# TC37XPD register map
Vendor: Infineon; Series: ATVMC; File version: 100
CPU: other r0p0, little endian, MPU, FPU, vendor SysTick, 4 interrupt priority bits
Registers are 32-bit, read-write, reset 0x0 unless marked. A register's access mark holds for its fields unless they carry their own. Offsets are from the block's base; [hi:lo] are bit positions; lines under a group give offsets from that group; {n}, {i} and the like mark numbered series; 'fields as' and 'values as' point back to an identical list.

## GTM (part 4 of 13)
Base 0xF0100000
{0x8000+0x800*i} TOM[{i}] (i=0..2) group
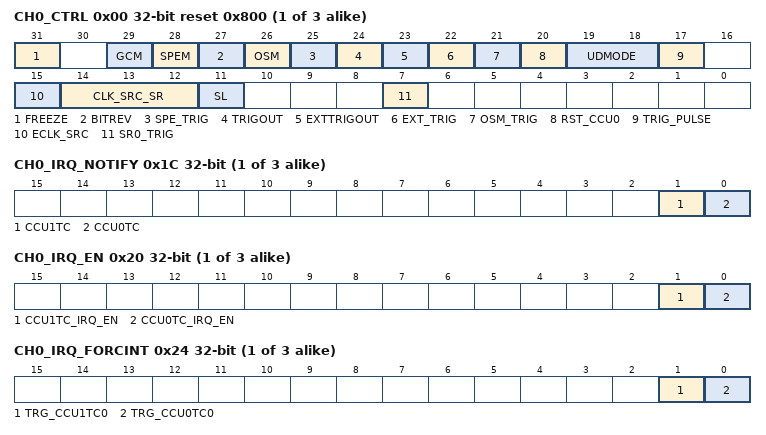
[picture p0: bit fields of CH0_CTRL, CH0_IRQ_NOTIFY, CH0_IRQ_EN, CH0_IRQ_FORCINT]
  0x00 CH0_CTRL reset 0x800 — TOM0 Channel 15 Control Register resetvalue={Application Reset:0x0800}
    [31] FREEZE
    [29] GCM — Gated Counter Mode enable. The Gated Counter mode is only available for TOM instances connected to an SPE module and only for channels 0 to 7.
    [28] SPEM — SPE output mode enable for channel. Note The SPE output mode is only implemented for TOM instances connected to an SPE module and only for TOM channels 0 to 7. Note For TOM channel 2 6 and 7 this bit defines in combination with bit SPE TRIG the source of output pin TOM i CH x OUT and if CN0 can be reset by TOM input signal SPE i NIPD .
    [27] BITREV — Bit reversing of output of counter register CN0. Note This bit enables the PCM mode of channel 15.
    [26] OSM — One shot mode. In this mode the counter CN0 counts for only one period. The length of period is defined by CM0. A write access to the register CN0 triggers the start of counting.
    [25] SPE_TRIG — SPE trigger to reset CN0. For TOM channel 2 6 and 7 this bit defines in combination with bit SPEM the source of output pin TOM i CH x OUT and if CN0 can be reset by TOM input signal SPE i NIPD. For TOM channel 8 and 9 this bit defines only if CN0 reset is defined by input signal SPE i NIPD or by configuration of RST CCU0. The output TOM i CH x OUT is not affected. The configuration bit SPEM is not available for these channels and thus assumed to be 0. If a configuration of SPEM SPE TRIG 0 1 or 1 0 is chosen i.e. CN0 is reset by signal SPE i NIPD the one shot mode in corresponding TOM channel should also be enabled by setting bit OSM 1 to generate one PWM pulse in case of trigger SPE i NIPD. In SPE module one of the trigger signals TOM i CH2 TRIG CCU1 TOM i CH6 TRIG CCU1 TOM i CH7 TRIG CCU1 TOM i CH8 TRIG CCU1 or TOM i CH9 TRIG CCU1 can be used to trigger the update of register SPE i OUT CTRL. If SPEM 0 SPEM 1
    [24] TRIGOUT — Trigger output selection output signal TRIG x of module TOM CH x
    [23] EXTTRIGOUT — TIM EXT CAPTURE x as potential output signal TRIG x
    [22] EXT_TRIG — Select TIM EXT CAPTURE x as trigger signal
    [21] OSM_TRIG — Enable trigger of one shot pulse by trigger signal OSM TRIG. Note This bit should only be set if bit OSM 1 and bit RST CCU0 0.
    [20] RST_CCU0 — Reset source of CCU0. On TOM channel 2 SPEM 1 has special meaning. If SPEM 1 the signal SPE NIPD triggers the reset of CN0 independent of RST CN0. This bit should only be set if bit OSM 0 i.e. in continuous mode .
    [19:18] UDMODE — Up down counter mode
    [17] TRIG_PULSE — Trigger output pulse length of one SYS CLK period
    [15] ECLK_SRC — Extend CLK SRC
    [14:12] CLK_SRC_SR — Clock source select for channel. The register CLK SRC is updated with the value of CLK SRC SR together with the update of register CM0 and CM1. The input of the FX clock divider depends on the value of FXCLK SEL see CMU . This register is a shadow register for the register CLK SRC. Thus if the CMU CLK source for PWM generation should be changed during operation the old CMU CLK has to operate until the update of the ATOM channels internal CLK SRC register by the CLK SRC SR content is done either by an end of a period or a forced update. If clock of channel is stopped i.e. ECLK SRC 0 and CLK SRC 101 110 111 the channel can only be restarted by resetting CLK SRC SR to a value of 000 to 100 and forcing an update via the force update mechanism. If ECLK SRC 0 ECLK SRC 1
    [11] SL — Signal level for duty cycle. If the output is disabled the output TOM OUT x is set to the inverse value of SL. Reset value depends on the hardware configuration chosen by silicon vendor.
    [7] SR0_TRIG — SR0 is used to generate a trigger on output TOM i CH x OUT T if equal to CN0. Note This bit should only be set if RST CCU0 of this channel is 0.
  0x04 CH0_SR0 — TOM0 Channel 15 CCU0 Compare Shadow Register resetvalue={Application Reset:0x0}
    [15:0] SR0 — TOM channel x shadow register SR0 for update of compare register CM0
  0x08 CH0_SR1 — TOM0 Channel 15 CCU1 Compare Shadow Register resetvalue={Application Reset:0x0}
    [15:0] SR1 — TOM channel x shadow register SR1 for update of compare register CM1
  0x0C CH0_CM0 — TOM0 Channel 15 CCU0 Compare Register resetvalue={Application Reset:0x0}
    [15:0] CM0 — TOM CCU0 compare register. Setting CM0 lt CM1 configures a duty cycle of 100 .
  0x10 CH0_CM1 — TOM0 Channel 15 CCU1 Compare Register resetvalue={Application Reset:0x0}
    [15:0] CM1 — TOM CCU1 compare register. Setting CM1 0 configures a duty cycle of 0 independent of the configured value of CM0.
  0x14 CH0_CN0 — TOM0 Channel 15 CCU0 Counter Register resetvalue={Application Reset:0x0}
    [15:0] CN0 — TOM CCU0 counter register. This counter is stopped if the TOM channel is disabled and not reset on an enable event of TOM channel.
  0x18 CH0_STAT ro — TOM0 Channel 15 Status Register resetvalue={Application Reset:0x0}
    [0] OL — Output level of output TOM OUT x . Reset value is the inverted value of SL bit which depends on the hardware configuration chosen by silicon vendor.
  0x1C CH0_IRQ_NOTIFY — TOM0 Channel 15 Interrupt Notification Register resetvalue={Application Reset:0x0}
    [1] CCU1TC — CCU1 Trigger condition interrupt for channel x. The notification of the interrupt is only triggered one time after reaching the condition CN0 gt CM1. To enable re trigger of the notification first the condition CN0 lt CM1 has to be reached. Note This bit will be cleared on a CPU write access of value 1. A read access leaves the bit unchanged. Note This description differs to the description in the Bosch spec.
    [0] CCU0TC — CCU0 Trigger condition interrupt for channel x. The notification of the interrupt is only triggered one time after reaching the condition CN0 gt CM0. To enable re trigger of the notification first the condition CN0 lt CM1 has to be reached. Note This bit will be cleared on a CPU write access of value 1. A read access leaves the bit unchanged. Note This description differs to the description in the Bosch spec.
  0x20 CH0_IRQ_EN — TOM0 Channel 15 Interrupt Enable Register resetvalue={Application Reset:0x0}
    [1] CCU1TC_IRQ_EN — TOM CCU1TC IRQ interrupt enable. Coding see bit 0.
    [0] CCU0TC_IRQ_EN — TOM CCU0TC IRQ interrupt enable
  0x24 CH0_IRQ_FORCINT — TOM0 Channel 15 Force Interrupt Register resetvalue={Application Reset:0x0}
    [1] TRG_CCU1TC0 — Trigger TOM CCU1TC0 IRQ interrupt by software. This bit is cleared automatically after write. This bit is write protected by bit RF PROT of register GTM CTRL.
    [0] TRG_CCU0TC0 — Trigger TOM CCU0TC0 IRQ interrupt by software. This bit is cleared automatically after write. This bit is write protected by bit RF PROT of register GTM CTRL
  0x28 CH0_IRQ_MODE — TOM0 Channel 15 Interrupt Mode Register resetvalue={Application Reset:0x0}
    [1:0] IRQ_MODE — IRQ mode selection. The interrupt modes are described in CROSSREFERENCE .
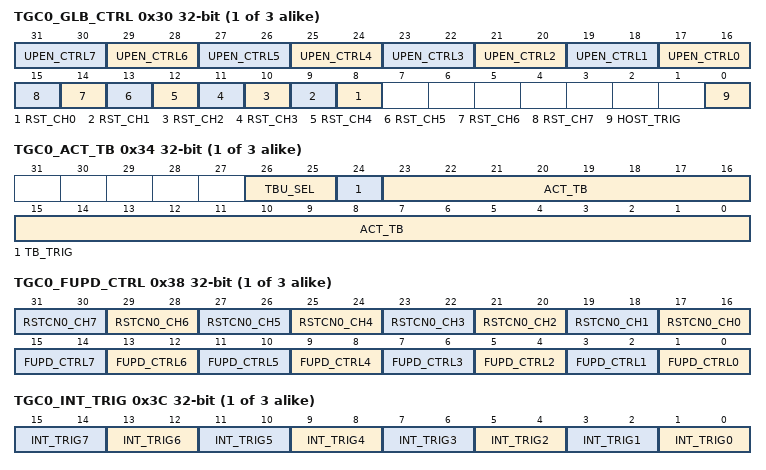
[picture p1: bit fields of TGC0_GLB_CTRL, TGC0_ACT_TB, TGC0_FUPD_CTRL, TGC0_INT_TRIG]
  0x30 TGC0_GLB_CTRL access per field — TOM0 TGC0 Global Control Register resetvalue={Application Reset:0x0}
    [2n+17:2n+16] UPEN_CTRL{n} rw (n=0..7) — TOM channel 7 enable update of register CM0 CM1 and CLK SRC from SR0 SR1 and CLK SRC SR. Write Read
    [n+8] RST_CH{n} wo (n=0..7) — Software reset of channel 7. This bit is cleared automatically after write by CPU. The channel register are set to their reset values and channel x operation is stopped immediately. The SR flip flop SOUR is set to 1 .
    [0] HOST_TRIG wo — Trigger request signal see TGC0 TGC1 to update the register ENDIS STAT and OUTEN STAT. This flag is reset automatically after triggering the update.
  0x34 TGC0_ACT_TB — TOM0 TGC0 Action Time Base Register resetvalue={Application Reset:0x0}
    [26:25] TBU_SEL — Selection of time base used for comparison. The bit combination 0b10 is only applicable if the TBU of the device contains three time base channels. Otherwise this bit combination is also reserved. Please refer to GTM Architecture block diagram on page 3 to determine the number of channels for TBU of this device.
    [24] TB_TRIG — Set trigger request. This flag is reset automatically if the selected time base unit TBU TS0 or TBU TS1 or TBU TS2 if present has reached the value ACT TB and the update of the register was triggered.
    [23:0] ACT_TB — Time base value. Specifies the signed compare value with selected signal TBU TS x x 0..2 If selected TBU TS x value is in the interval ACT TB 007FFFFFh ACT TB the event is in the past and the trigger is generated immediately. Otherwise the event is in the future and the trigger is generated if selected TBU TS x is equal to ACT TB .
  0x38 TGC0_FUPD_CTRL — TOM0 TGC0 Force Update Control Register resetvalue={Application Reset:0x0}
    [2n+17:2n+16] RSTCN0_CH{n} (n=0..7) — Reset CN0 of channel 7 on force update event. If enabled reset CN0 triggered by HOST TRIG ACT TB compare match or internal trigger. Write Read
    [2n+1:2n] FUPD_CTRL{n} (n=0..7) — Force update of TOM channel 7 operation registers. If enabled force update of register CM0 CM1 and CLK SRC triggered by HOST TRIG ACT TB compare match or internal trigger. Write Read The force update request is stored and executed synchronized to the selected FXCLK.
  0x3C TGC0_INT_TRIG — TOM0 TGC0 Internal Trigger Control Register resetvalue={Application Reset:0x0}
    [2n+1:2n] INT_TRIG{n} (n=0..7) — Select input signal TRIG 7 as a trigger source. Write Read
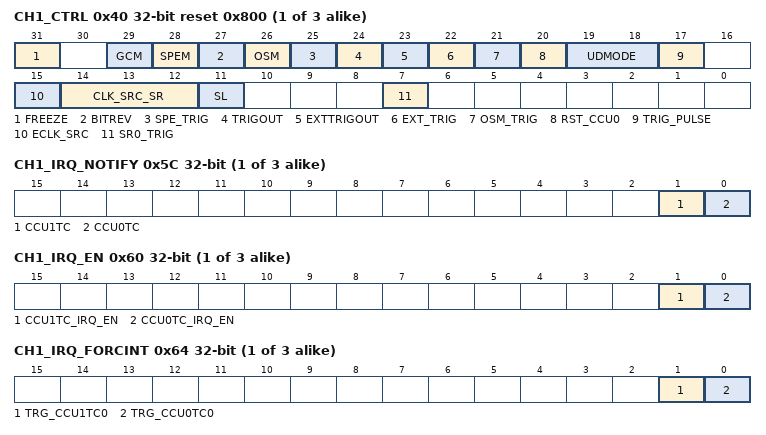
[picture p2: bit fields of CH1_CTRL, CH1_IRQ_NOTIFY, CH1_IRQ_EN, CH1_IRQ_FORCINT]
  0x40 CH1_CTRL reset 0x800 — TOM0 Channel 15 Control Register resetvalue={Application Reset:0x0800}
    fields as TOM[0].CH0_CTRL
  0x44 CH1_SR0 — TOM0 Channel 15 CCU0 Compare Shadow Register resetvalue={Application Reset:0x0}
    fields as TOM[0].CH0_SR0
  0x48 CH1_SR1 — TOM0 Channel 15 CCU1 Compare Shadow Register resetvalue={Application Reset:0x0}
    fields as TOM[0].CH0_SR1
  0x4C CH1_CM0 — TOM0 Channel 15 CCU0 Compare Register resetvalue={Application Reset:0x0}
    fields as TOM[0].CH0_CM0
  0x50 CH1_CM1 — TOM0 Channel 15 CCU1 Compare Register resetvalue={Application Reset:0x0}
    fields as TOM[0].CH0_CM1
  0x54 CH1_CN0 — TOM0 Channel 15 CCU0 Counter Register resetvalue={Application Reset:0x0}
    fields as TOM[0].CH0_CN0
  0x58 CH1_STAT ro — TOM0 Channel 15 Status Register resetvalue={Application Reset:0x0}
    fields as TOM[0].CH0_STAT
  0x5C CH1_IRQ_NOTIFY — TOM0 Channel 15 Interrupt Notification Register resetvalue={Application Reset:0x0}
    fields as TOM[0].CH0_IRQ_NOTIFY
  0x60 CH1_IRQ_EN — TOM0 Channel 15 Interrupt Enable Register resetvalue={Application Reset:0x0}
    fields as TOM[0].CH0_IRQ_EN
  0x64 CH1_IRQ_FORCINT — TOM0 Channel 15 Force Interrupt Register resetvalue={Application Reset:0x0}
    fields as TOM[0].CH0_IRQ_FORCINT
  0x68 CH1_IRQ_MODE — TOM0 Channel 15 Interrupt Mode Register resetvalue={Application Reset:0x0}
    fields as TOM[0].CH0_IRQ_MODE
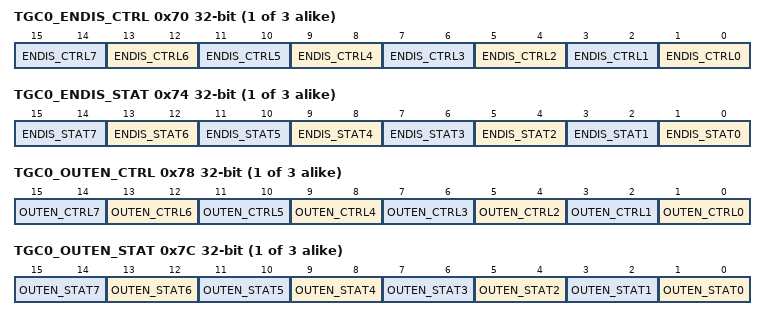
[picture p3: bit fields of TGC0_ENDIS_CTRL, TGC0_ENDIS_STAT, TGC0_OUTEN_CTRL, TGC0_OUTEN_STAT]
  0x70 TGC0_ENDIS_CTRL — TOM0 TGC0 Enable Disable Control Register resetvalue={Application Reset:0x0}
    [2n+1:2n] ENDIS_CTRL{n} (n=0..7) — TOM channel 7 enable disable update value. If FREEZE 0 If a TOM channel is disabled the counter CN0 is stopped and the output register of SOU unit is set to the inverse value of control bit SL. On an enable event the counter CN0 starts counting from its current value. If FREEZE 1 If a TOM channel is disabled the counter CN0 is stopped. On an enable event the counter CN0 starts counting from its current value. Write of following double bit values is possible If the output is disabled OUTEN 0 0 the TOM channel 0 output TOM i CH0 OUT is the inverted value of bit SL.
  0x74 TGC0_ENDIS_STAT — TOM0 TGC0 Enable Disable Status Register resetvalue={Application Reset:0x0}
    [2n+1:2n] ENDIS_STAT{n} (n=0..7) — TOM channel 7 enable disable update value. If FREEZE 0 If a TOM channel is disabled the counter CN0 is stopped and the output register of SOU unit is set to the inverse value of control bit SL. On an enable event the counter CN0 starts counting from its current value. If FREEZE 1 If a TOM channel is disabled the counter CN0 is stopped. On an enable event the counter CN0 starts counting from its current value. Write of following double bit values is possible
  0x78 TGC0_OUTEN_CTRL — TOM0 TGC0 Output Enable Control Register resetvalue={Application Reset:0x0}
    [2n+1:2n] OUTEN_CTRL{n} (n=0..7) — Output TOM i CH7 OUT enable disable update value. Write of following double bit values is possible If the channel is disabled ENDIS 0 0 or the output is disabled OUTEN 0 0 the TOM channel 0 output TOM i CH0 OUT is the inverted value of bit SL.
  0x7C TGC0_OUTEN_STAT — TOM0 TGC0 Output Enable Status Register resetvalue={Application Reset:0x0}
    [2n+1:2n] OUTEN_STAT{n} (n=0..7) — Control status of output TOM i CH7 OUT. Write of following double bit values is possible
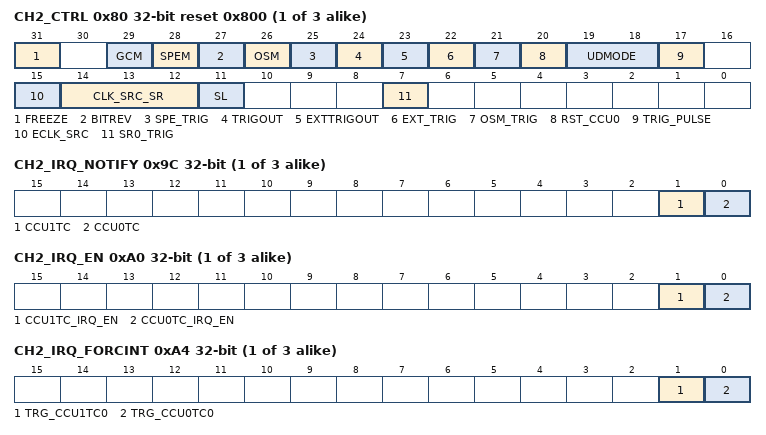
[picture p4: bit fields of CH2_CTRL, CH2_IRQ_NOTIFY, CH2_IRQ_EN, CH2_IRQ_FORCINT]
  0x80 CH2_CTRL reset 0x800 — TOM0 Channel 15 Control Register resetvalue={Application Reset:0x0800}
    fields as TOM[0].CH0_CTRL
  0x84 CH2_SR0 — TOM0 Channel 15 CCU0 Compare Shadow Register resetvalue={Application Reset:0x0}
    fields as TOM[0].CH0_SR0
  0x88 CH2_SR1 — TOM0 Channel 15 CCU1 Compare Shadow Register resetvalue={Application Reset:0x0}
    fields as TOM[0].CH0_SR1
  0x8C CH2_CM0 — TOM0 Channel 15 CCU0 Compare Register resetvalue={Application Reset:0x0}
    fields as TOM[0].CH0_CM0
  0x90 CH2_CM1 — TOM0 Channel 15 CCU1 Compare Register resetvalue={Application Reset:0x0}
    fields as TOM[0].CH0_CM1
  0x94 CH2_CN0 — TOM0 Channel 15 CCU0 Counter Register resetvalue={Application Reset:0x0}
    fields as TOM[0].CH0_CN0
  0x98 CH2_STAT ro — TOM0 Channel 15 Status Register resetvalue={Application Reset:0x0}
    fields as TOM[0].CH0_STAT
  0x9C CH2_IRQ_NOTIFY — TOM0 Channel 15 Interrupt Notification Register resetvalue={Application Reset:0x0}
    fields as TOM[0].CH0_IRQ_NOTIFY
  0xA0 CH2_IRQ_EN — TOM0 Channel 15 Interrupt Enable Register resetvalue={Application Reset:0x0}
    fields as TOM[0].CH0_IRQ_EN
  0xA4 CH2_IRQ_FORCINT — TOM0 Channel 15 Force Interrupt Register resetvalue={Application Reset:0x0}
    fields as TOM[0].CH0_IRQ_FORCINT
  0xA8 CH2_IRQ_MODE — TOM0 Channel 15 Interrupt Mode Register resetvalue={Application Reset:0x0}
    fields as TOM[0].CH0_IRQ_MODE
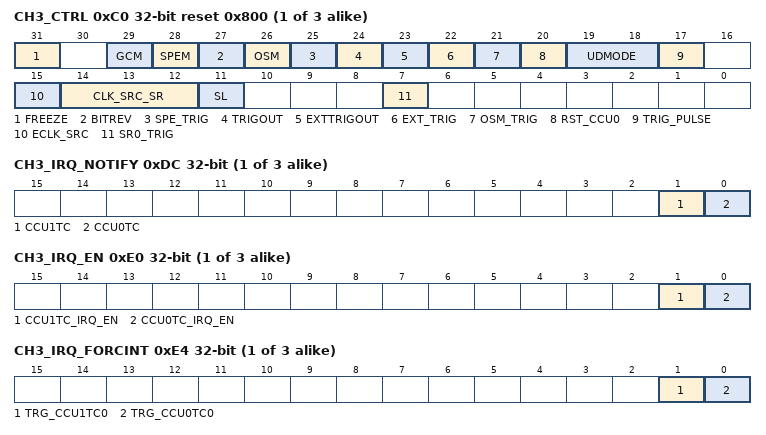
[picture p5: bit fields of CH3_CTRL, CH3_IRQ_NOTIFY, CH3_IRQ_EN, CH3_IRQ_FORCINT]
  0xC0 CH3_CTRL reset 0x800 — TOM0 Channel 15 Control Register resetvalue={Application Reset:0x0800}
    fields as TOM[0].CH0_CTRL
  0xC4 CH3_SR0 — TOM0 Channel 15 CCU0 Compare Shadow Register resetvalue={Application Reset:0x0}
    fields as TOM[0].CH0_SR0
  0xC8 CH3_SR1 — TOM0 Channel 15 CCU1 Compare Shadow Register resetvalue={Application Reset:0x0}
    fields as TOM[0].CH0_SR1
  0xCC CH3_CM0 — TOM0 Channel 15 CCU0 Compare Register resetvalue={Application Reset:0x0}
    fields as TOM[0].CH0_CM0
  0xD0 CH3_CM1 — TOM0 Channel 15 CCU1 Compare Register resetvalue={Application Reset:0x0}
    fields as TOM[0].CH0_CM1
  0xD4 CH3_CN0 — TOM0 Channel 15 CCU0 Counter Register resetvalue={Application Reset:0x0}
    fields as TOM[0].CH0_CN0
  0xD8 CH3_STAT ro — TOM0 Channel 15 Status Register resetvalue={Application Reset:0x0}
    fields as TOM[0].CH0_STAT
  0xDC CH3_IRQ_NOTIFY — TOM0 Channel 15 Interrupt Notification Register resetvalue={Application Reset:0x0}
    fields as TOM[0].CH0_IRQ_NOTIFY
  0xE0 CH3_IRQ_EN — TOM0 Channel 15 Interrupt Enable Register resetvalue={Application Reset:0x0}
    fields as TOM[0].CH0_IRQ_EN
  0xE4 CH3_IRQ_FORCINT — TOM0 Channel 15 Force Interrupt Register resetvalue={Application Reset:0x0}
    fields as TOM[0].CH0_IRQ_FORCINT
  0xE8 CH3_IRQ_MODE — TOM0 Channel 15 Interrupt Mode Register resetvalue={Application Reset:0x0}
    fields as TOM[0].CH0_IRQ_MODE
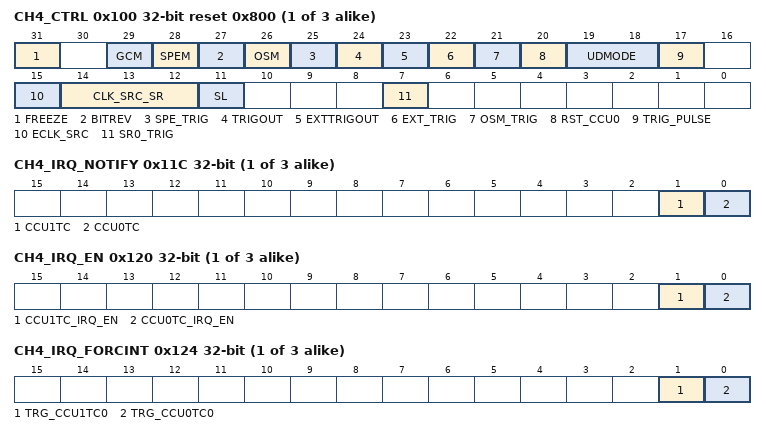
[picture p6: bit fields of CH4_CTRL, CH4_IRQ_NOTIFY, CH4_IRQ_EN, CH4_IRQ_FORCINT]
  0x100 CH4_CTRL reset 0x800 — TOM0 Channel 15 Control Register resetvalue={Application Reset:0x0800}
    fields as TOM[0].CH0_CTRL
  0x104 CH4_SR0 — TOM0 Channel 15 CCU0 Compare Shadow Register resetvalue={Application Reset:0x0}
    fields as TOM[0].CH0_SR0
  0x108 CH4_SR1 — TOM0 Channel 15 CCU1 Compare Shadow Register resetvalue={Application Reset:0x0}
    fields as TOM[0].CH0_SR1
  0x10C CH4_CM0 — TOM0 Channel 15 CCU0 Compare Register resetvalue={Application Reset:0x0}
    fields as TOM[0].CH0_CM0
  0x110 CH4_CM1 — TOM0 Channel 15 CCU1 Compare Register resetvalue={Application Reset:0x0}
    fields as TOM[0].CH0_CM1
  0x114 CH4_CN0 — TOM0 Channel 15 CCU0 Counter Register resetvalue={Application Reset:0x0}
    fields as TOM[0].CH0_CN0
  0x118 CH4_STAT ro — TOM0 Channel 15 Status Register resetvalue={Application Reset:0x0}
    fields as TOM[0].CH0_STAT
  0x11C CH4_IRQ_NOTIFY — TOM0 Channel 15 Interrupt Notification Register resetvalue={Application Reset:0x0}
    fields as TOM[0].CH0_IRQ_NOTIFY
  0x120 CH4_IRQ_EN — TOM0 Channel 15 Interrupt Enable Register resetvalue={Application Reset:0x0}
    fields as TOM[0].CH0_IRQ_EN
  0x124 CH4_IRQ_FORCINT — TOM0 Channel 15 Force Interrupt Register resetvalue={Application Reset:0x0}
    fields as TOM[0].CH0_IRQ_FORCINT
  0x128 CH4_IRQ_MODE — TOM0 Channel 15 Interrupt Mode Register resetvalue={Application Reset:0x0}
    fields as TOM[0].CH0_IRQ_MODE
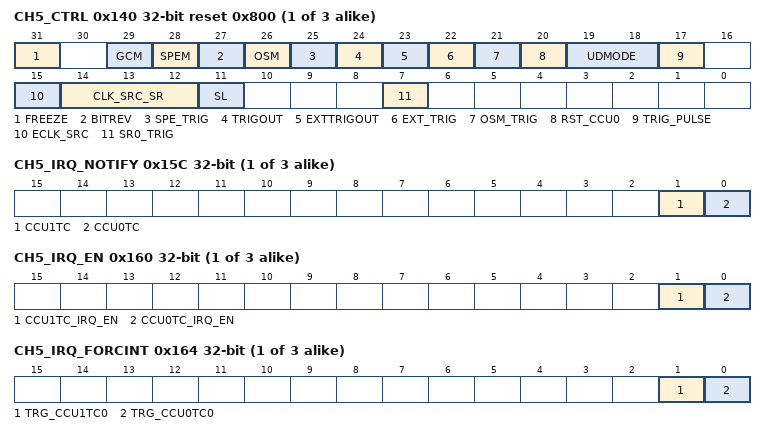
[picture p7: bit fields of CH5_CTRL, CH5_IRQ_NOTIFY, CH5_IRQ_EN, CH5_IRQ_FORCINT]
  0x140 CH5_CTRL reset 0x800 — TOM0 Channel 15 Control Register resetvalue={Application Reset:0x0800}
    fields as TOM[0].CH0_CTRL
  0x144 CH5_SR0 — TOM0 Channel 15 CCU0 Compare Shadow Register resetvalue={Application Reset:0x0}
    fields as TOM[0].CH0_SR0
  0x148 CH5_SR1 — TOM0 Channel 15 CCU1 Compare Shadow Register resetvalue={Application Reset:0x0}
    fields as TOM[0].CH0_SR1
  0x14C CH5_CM0 — TOM0 Channel 15 CCU0 Compare Register resetvalue={Application Reset:0x0}
    fields as TOM[0].CH0_CM0
  0x150 CH5_CM1 — TOM0 Channel 15 CCU1 Compare Register resetvalue={Application Reset:0x0}
    fields as TOM[0].CH0_CM1
  0x154 CH5_CN0 — TOM0 Channel 15 CCU0 Counter Register resetvalue={Application Reset:0x0}
    fields as TOM[0].CH0_CN0
  0x158 CH5_STAT ro — TOM0 Channel 15 Status Register resetvalue={Application Reset:0x0}
    fields as TOM[0].CH0_STAT
  0x15C CH5_IRQ_NOTIFY — TOM0 Channel 15 Interrupt Notification Register resetvalue={Application Reset:0x0}
    fields as TOM[0].CH0_IRQ_NOTIFY
  0x160 CH5_IRQ_EN — TOM0 Channel 15 Interrupt Enable Register resetvalue={Application Reset:0x0}
    fields as TOM[0].CH0_IRQ_EN
  0x164 CH5_IRQ_FORCINT — TOM0 Channel 15 Force Interrupt Register resetvalue={Application Reset:0x0}
    fields as TOM[0].CH0_IRQ_FORCINT
  0x168 CH5_IRQ_MODE — TOM0 Channel 15 Interrupt Mode Register resetvalue={Application Reset:0x0}
    fields as TOM[0].CH0_IRQ_MODE
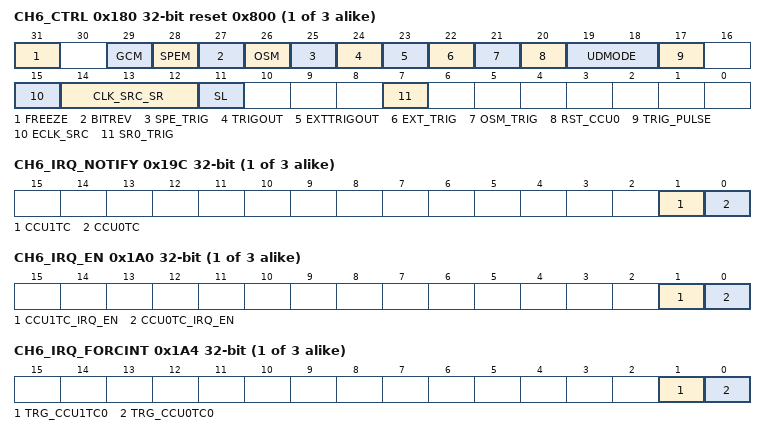
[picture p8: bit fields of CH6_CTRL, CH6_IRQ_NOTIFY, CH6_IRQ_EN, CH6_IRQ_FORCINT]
  0x180 CH6_CTRL reset 0x800 — TOM0 Channel 15 Control Register resetvalue={Application Reset:0x0800}
    fields as TOM[0].CH0_CTRL
  0x184 CH6_SR0 — TOM0 Channel 15 CCU0 Compare Shadow Register resetvalue={Application Reset:0x0}
    fields as TOM[0].CH0_SR0
  0x188 CH6_SR1 — TOM0 Channel 15 CCU1 Compare Shadow Register resetvalue={Application Reset:0x0}
    fields as TOM[0].CH0_SR1
  0x18C CH6_CM0 — TOM0 Channel 15 CCU0 Compare Register resetvalue={Application Reset:0x0}
    fields as TOM[0].CH0_CM0
  0x190 CH6_CM1 — TOM0 Channel 15 CCU1 Compare Register resetvalue={Application Reset:0x0}
    fields as TOM[0].CH0_CM1
  0x194 CH6_CN0 — TOM0 Channel 15 CCU0 Counter Register resetvalue={Application Reset:0x0}
    fields as TOM[0].CH0_CN0
  0x198 CH6_STAT ro — TOM0 Channel 15 Status Register resetvalue={Application Reset:0x0}
    fields as TOM[0].CH0_STAT
  0x19C CH6_IRQ_NOTIFY — TOM0 Channel 15 Interrupt Notification Register resetvalue={Application Reset:0x0}
    fields as TOM[0].CH0_IRQ_NOTIFY
  0x1A0 CH6_IRQ_EN — TOM0 Channel 15 Interrupt Enable Register resetvalue={Application Reset:0x0}
    fields as TOM[0].CH0_IRQ_EN
  0x1A4 CH6_IRQ_FORCINT — TOM0 Channel 15 Force Interrupt Register resetvalue={Application Reset:0x0}
    fields as TOM[0].CH0_IRQ_FORCINT
  0x1A8 CH6_IRQ_MODE — TOM0 Channel 15 Interrupt Mode Register resetvalue={Application Reset:0x0}
    fields as TOM[0].CH0_IRQ_MODE
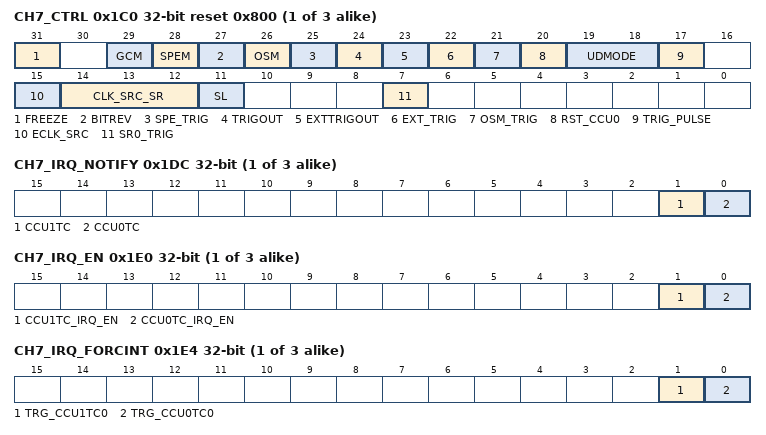
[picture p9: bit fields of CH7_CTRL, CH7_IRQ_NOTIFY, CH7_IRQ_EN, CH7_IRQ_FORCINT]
  0x1C0 CH7_CTRL reset 0x800 — TOM0 Channel 15 Control Register resetvalue={Application Reset:0x0800}
    fields as TOM[0].CH0_CTRL
  0x1C4 CH7_SR0 — TOM0 Channel 15 CCU0 Compare Shadow Register resetvalue={Application Reset:0x0}
    fields as TOM[0].CH0_SR0
  0x1C8 CH7_SR1 — TOM0 Channel 15 CCU1 Compare Shadow Register resetvalue={Application Reset:0x0}
    fields as TOM[0].CH0_SR1
  0x1CC CH7_CM0 — TOM0 Channel 15 CCU0 Compare Register resetvalue={Application Reset:0x0}
    fields as TOM[0].CH0_CM0
  0x1D0 CH7_CM1 — TOM0 Channel 15 CCU1 Compare Register resetvalue={Application Reset:0x0}
    fields as TOM[0].CH0_CM1
  0x1D4 CH7_CN0 — TOM0 Channel 15 CCU0 Counter Register resetvalue={Application Reset:0x0}
    fields as TOM[0].CH0_CN0
  0x1D8 CH7_STAT ro — TOM0 Channel 15 Status Register resetvalue={Application Reset:0x0}
    fields as TOM[0].CH0_STAT
  0x1DC CH7_IRQ_NOTIFY — TOM0 Channel 15 Interrupt Notification Register resetvalue={Application Reset:0x0}
    fields as TOM[0].CH0_IRQ_NOTIFY
  0x1E0 CH7_IRQ_EN — TOM0 Channel 15 Interrupt Enable Register resetvalue={Application Reset:0x0}
    fields as TOM[0].CH0_IRQ_EN
  0x1E4 CH7_IRQ_FORCINT — TOM0 Channel 15 Force Interrupt Register resetvalue={Application Reset:0x0}
    fields as TOM[0].CH0_IRQ_FORCINT
  0x1E8 CH7_IRQ_MODE — TOM0 Channel 15 Interrupt Mode Register resetvalue={Application Reset:0x0}
    fields as TOM[0].CH0_IRQ_MODE
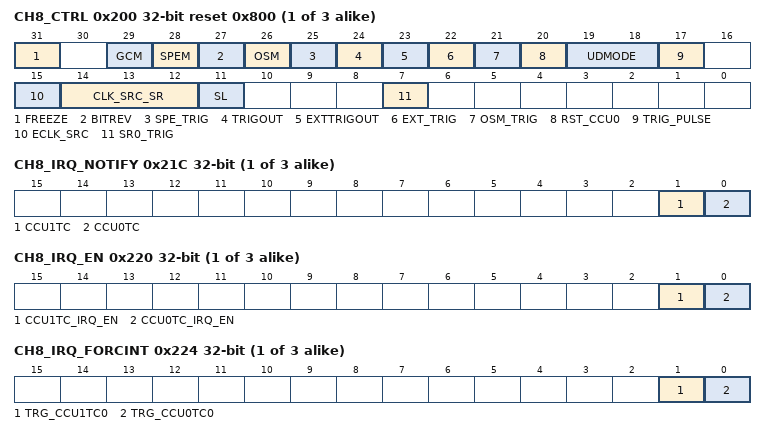
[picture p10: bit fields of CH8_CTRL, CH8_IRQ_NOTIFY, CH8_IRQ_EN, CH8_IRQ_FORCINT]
  0x200 CH8_CTRL reset 0x800 — TOM0 Channel 15 Control Register resetvalue={Application Reset:0x0800}
    fields as TOM[0].CH0_CTRL
  0x204 CH8_SR0 — TOM0 Channel 15 CCU0 Compare Shadow Register resetvalue={Application Reset:0x0}
    fields as TOM[0].CH0_SR0
  0x208 CH8_SR1 — TOM0 Channel 15 CCU1 Compare Shadow Register resetvalue={Application Reset:0x0}
    fields as TOM[0].CH0_SR1
  0x20C CH8_CM0 — TOM0 Channel 15 CCU0 Compare Register resetvalue={Application Reset:0x0}
    fields as TOM[0].CH0_CM0
  0x210 CH8_CM1 — TOM0 Channel 15 CCU1 Compare Register resetvalue={Application Reset:0x0}
    fields as TOM[0].CH0_CM1
  0x214 CH8_CN0 — TOM0 Channel 15 CCU0 Counter Register resetvalue={Application Reset:0x0}
    fields as TOM[0].CH0_CN0
  0x218 CH8_STAT ro — TOM0 Channel 15 Status Register resetvalue={Application Reset:0x0}
    fields as TOM[0].CH0_STAT
  0x21C CH8_IRQ_NOTIFY — TOM0 Channel 15 Interrupt Notification Register resetvalue={Application Reset:0x0}
    fields as TOM[0].CH0_IRQ_NOTIFY
  0x220 CH8_IRQ_EN — TOM0 Channel 15 Interrupt Enable Register resetvalue={Application Reset:0x0}
    fields as TOM[0].CH0_IRQ_EN
  0x224 CH8_IRQ_FORCINT — TOM0 Channel 15 Force Interrupt Register resetvalue={Application Reset:0x0}
    fields as TOM[0].CH0_IRQ_FORCINT
  0x228 CH8_IRQ_MODE — TOM0 Channel 15 Interrupt Mode Register resetvalue={Application Reset:0x0}
    fields as TOM[0].CH0_IRQ_MODE
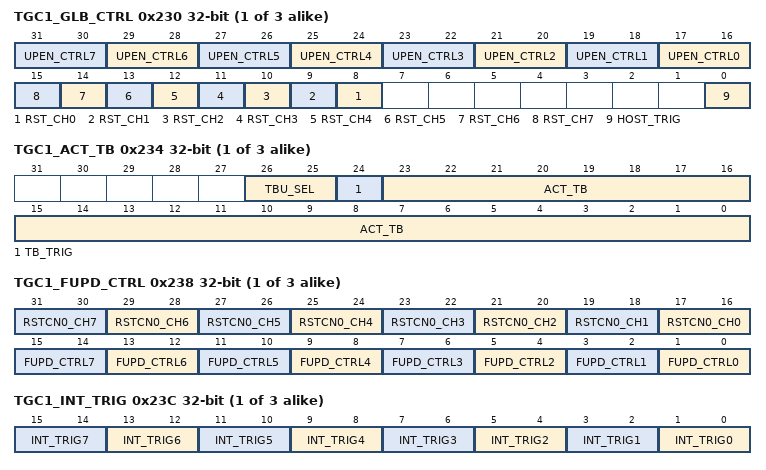
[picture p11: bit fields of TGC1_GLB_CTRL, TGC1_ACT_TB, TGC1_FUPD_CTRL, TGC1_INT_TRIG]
  0x230 TGC1_GLB_CTRL access per field — TOM0 TGC1 Global Control Register resetvalue={Application Reset:0x0}
    fields as TOM[0].TGC0_GLB_CTRL
  0x234 TGC1_ACT_TB — TOM0 TGC1 Action Time Base Register resetvalue={Application Reset:0x0}
    fields as TOM[0].TGC0_ACT_TB
  0x238 TGC1_FUPD_CTRL — TOM0 TGC1 Force Update Control Register resetvalue={Application Reset:0x0}
    fields as TOM[0].TGC0_FUPD_CTRL
  0x23C TGC1_INT_TRIG — TOM0 TGC1 Internal Trigger Control Register resetvalue={Application Reset:0x0}
    fields as TOM[0].TGC0_INT_TRIG
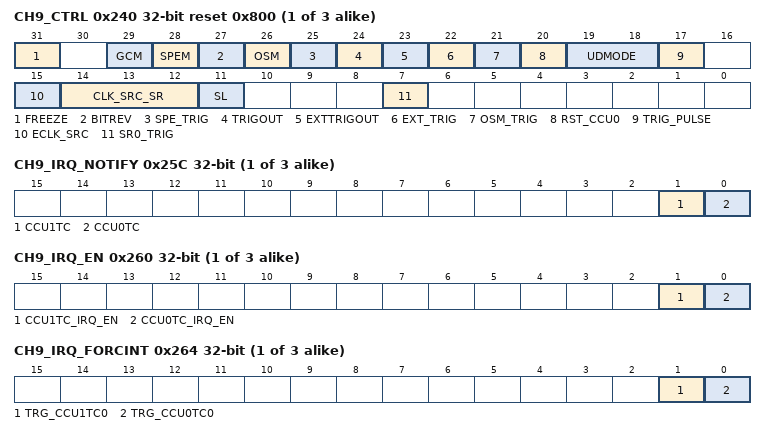
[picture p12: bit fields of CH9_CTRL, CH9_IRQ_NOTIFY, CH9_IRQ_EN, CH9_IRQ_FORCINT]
  0x240 CH9_CTRL reset 0x800 — TOM0 Channel 15 Control Register resetvalue={Application Reset:0x0800}
    fields as TOM[0].CH0_CTRL
  0x244 CH9_SR0 — TOM0 Channel 15 CCU0 Compare Shadow Register resetvalue={Application Reset:0x0}
    fields as TOM[0].CH0_SR0
  0x248 CH9_SR1 — TOM0 Channel 15 CCU1 Compare Shadow Register resetvalue={Application Reset:0x0}
    fields as TOM[0].CH0_SR1
  0x24C CH9_CM0 — TOM0 Channel 15 CCU0 Compare Register resetvalue={Application Reset:0x0}
    fields as TOM[0].CH0_CM0
  0x250 CH9_CM1 — TOM0 Channel 15 CCU1 Compare Register resetvalue={Application Reset:0x0}
    fields as TOM[0].CH0_CM1
  0x254 CH9_CN0 — TOM0 Channel 15 CCU0 Counter Register resetvalue={Application Reset:0x0}
    fields as TOM[0].CH0_CN0
  0x258 CH9_STAT ro — TOM0 Channel 15 Status Register resetvalue={Application Reset:0x0}
    fields as TOM[0].CH0_STAT
  0x25C CH9_IRQ_NOTIFY — TOM0 Channel 15 Interrupt Notification Register resetvalue={Application Reset:0x0}
    fields as TOM[0].CH0_IRQ_NOTIFY
  0x260 CH9_IRQ_EN — TOM0 Channel 15 Interrupt Enable Register resetvalue={Application Reset:0x0}
    fields as TOM[0].CH0_IRQ_EN
  0x264 CH9_IRQ_FORCINT — TOM0 Channel 15 Force Interrupt Register resetvalue={Application Reset:0x0}
    fields as TOM[0].CH0_IRQ_FORCINT
  0x268 CH9_IRQ_MODE — TOM0 Channel 15 Interrupt Mode Register resetvalue={Application Reset:0x0}
    fields as TOM[0].CH0_IRQ_MODE
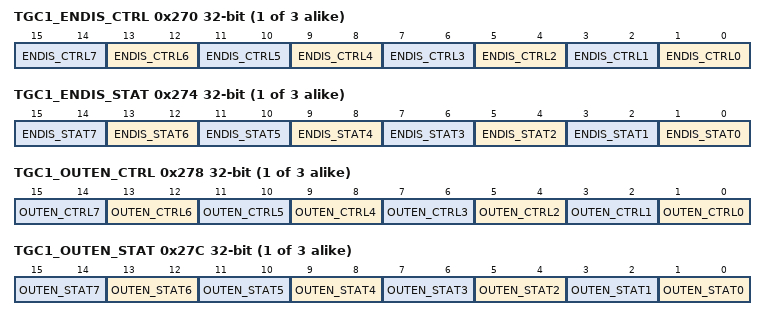
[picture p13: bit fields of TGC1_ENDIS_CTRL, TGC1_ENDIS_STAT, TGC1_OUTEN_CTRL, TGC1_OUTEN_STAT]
  0x270 TGC1_ENDIS_CTRL — TOM0 TGC1 Enable Disable Control Register resetvalue={Application Reset:0x0}
    fields as TOM[0].TGC0_ENDIS_CTRL
  0x274 TGC1_ENDIS_STAT — TOM0 TGC1 Enable Disable Status Register resetvalue={Application Reset:0x0}
    fields as TOM[0].TGC0_ENDIS_STAT
  0x278 TGC1_OUTEN_CTRL — TOM0 TGC1 Output Enable Control Register resetvalue={Application Reset:0x0}
    fields as TOM[0].TGC0_OUTEN_CTRL
  0x27C TGC1_OUTEN_STAT — TOM0 TGC1 Output Enable Status Register resetvalue={Application Reset:0x0}
    fields as TOM[0].TGC0_OUTEN_STAT
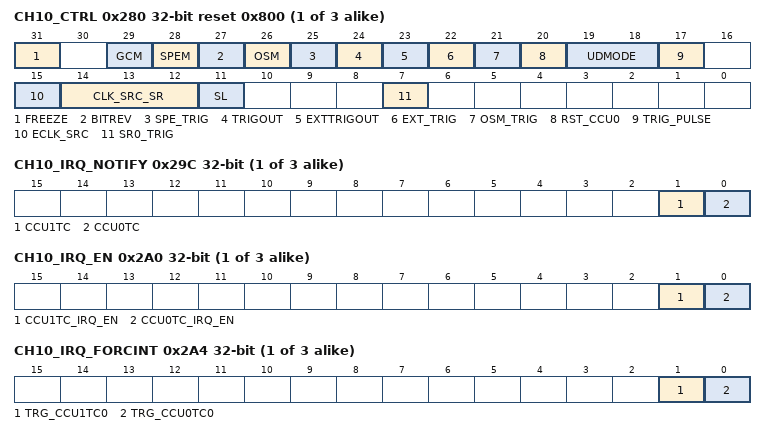
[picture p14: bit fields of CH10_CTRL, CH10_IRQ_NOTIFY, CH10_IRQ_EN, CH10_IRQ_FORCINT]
  0x280 CH10_CTRL reset 0x800 — TOM0 Channel 15 Control Register resetvalue={Application Reset:0x0800}
    fields as TOM[0].CH0_CTRL
  0x284 CH10_SR0 — TOM0 Channel 15 CCU0 Compare Shadow Register resetvalue={Application Reset:0x0}
    fields as TOM[0].CH0_SR0
  0x288 CH10_SR1 — TOM0 Channel 15 CCU1 Compare Shadow Register resetvalue={Application Reset:0x0}
    fields as TOM[0].CH0_SR1
  0x28C CH10_CM0 — TOM0 Channel 15 CCU0 Compare Register resetvalue={Application Reset:0x0}
    fields as TOM[0].CH0_CM0
  0x290 CH10_CM1 — TOM0 Channel 15 CCU1 Compare Register resetvalue={Application Reset:0x0}
    fields as TOM[0].CH0_CM1
  0x294 CH10_CN0 — TOM0 Channel 15 CCU0 Counter Register resetvalue={Application Reset:0x0}
    fields as TOM[0].CH0_CN0
  0x298 CH10_STAT ro — TOM0 Channel 15 Status Register resetvalue={Application Reset:0x0}
    fields as TOM[0].CH0_STAT
  0x29C CH10_IRQ_NOTIFY — TOM0 Channel 15 Interrupt Notification Register resetvalue={Application Reset:0x0}
    fields as TOM[0].CH0_IRQ_NOTIFY
  0x2A0 CH10_IRQ_EN — TOM0 Channel 15 Interrupt Enable Register resetvalue={Application Reset:0x0}
    fields as TOM[0].CH0_IRQ_EN
  0x2A4 CH10_IRQ_FORCINT — TOM0 Channel 15 Force Interrupt Register resetvalue={Application Reset:0x0}
    fields as TOM[0].CH0_IRQ_FORCINT
  0x2A8 CH10_IRQ_MODE — TOM0 Channel 15 Interrupt Mode Register resetvalue={Application Reset:0x0}
    fields as TOM[0].CH0_IRQ_MODE
  0x2C0 CH11_CTRL reset 0x800 — TOM0 Channel 15 Control Register resetvalue={Application Reset:0x0800}
    fields as TOM[0].CH0_CTRL
  0x2C4 CH11_SR0 — TOM0 Channel 15 CCU0 Compare Shadow Register resetvalue={Application Reset:0x0}
    fields as TOM[0].CH0_SR0
  0x2C8 CH11_SR1 — TOM0 Channel 15 CCU1 Compare Shadow Register resetvalue={Application Reset:0x0}
    fields as TOM[0].CH0_SR1
  0x2CC CH11_CM0 — TOM0 Channel 15 CCU0 Compare Register resetvalue={Application Reset:0x0}
    fields as TOM[0].CH0_CM0
  0x2D0 CH11_CM1 — TOM0 Channel 15 CCU1 Compare Register resetvalue={Application Reset:0x0}
    fields as TOM[0].CH0_CM1
  0x2D4 CH11_CN0 — TOM0 Channel 15 CCU0 Counter Register resetvalue={Application Reset:0x0}
    fields as TOM[0].CH0_CN0
  0x2D8 CH11_STAT ro — TOM0 Channel 15 Status Register resetvalue={Application Reset:0x0}
    fields as TOM[0].CH0_STAT
  0x2DC CH11_IRQ_NOTIFY — TOM0 Channel 15 Interrupt Notification Register resetvalue={Application Reset:0x0}
    fields as TOM[0].CH0_IRQ_NOTIFY
  0x2E0 CH11_IRQ_EN — TOM0 Channel 15 Interrupt Enable Register resetvalue={Application Reset:0x0}
    fields as TOM[0].CH0_IRQ_EN
  0x2E4 CH11_IRQ_FORCINT — TOM0 Channel 15 Force Interrupt Register resetvalue={Application Reset:0x0}
    fields as TOM[0].CH0_IRQ_FORCINT
  0x2E8 CH11_IRQ_MODE — TOM0 Channel 15 Interrupt Mode Register resetvalue={Application Reset:0x0}
    fields as TOM[0].CH0_IRQ_MODE
  0x300 CH12_CTRL reset 0x800 — TOM0 Channel 15 Control Register resetvalue={Application Reset:0x0800}
    fields as TOM[0].CH0_CTRL
  0x304 CH12_SR0 — TOM0 Channel 15 CCU0 Compare Shadow Register resetvalue={Application Reset:0x0}
    fields as TOM[0].CH0_SR0
  0x308 CH12_SR1 — TOM0 Channel 15 CCU1 Compare Shadow Register resetvalue={Application Reset:0x0}
    fields as TOM[0].CH0_SR1
  0x30C CH12_CM0 — TOM0 Channel 15 CCU0 Compare Register resetvalue={Application Reset:0x0}
    fields as TOM[0].CH0_CM0
  0x310 CH12_CM1 — TOM0 Channel 15 CCU1 Compare Register resetvalue={Application Reset:0x0}
    fields as TOM[0].CH0_CM1
  0x314 CH12_CN0 — TOM0 Channel 15 CCU0 Counter Register resetvalue={Application Reset:0x0}
    fields as TOM[0].CH0_CN0
  0x318 CH12_STAT ro — TOM0 Channel 15 Status Register resetvalue={Application Reset:0x0}
    fields as TOM[0].CH0_STAT
  0x31C CH12_IRQ_NOTIFY — TOM0 Channel 15 Interrupt Notification Register resetvalue={Application Reset:0x0}
    fields as TOM[0].CH0_IRQ_NOTIFY
  0x320 CH12_IRQ_EN — TOM0 Channel 15 Interrupt Enable Register resetvalue={Application Reset:0x0}
    fields as TOM[0].CH0_IRQ_EN
  0x324 CH12_IRQ_FORCINT — TOM0 Channel 15 Force Interrupt Register resetvalue={Application Reset:0x0}
    fields as TOM[0].CH0_IRQ_FORCINT
  0x328 CH12_IRQ_MODE — TOM0 Channel 15 Interrupt Mode Register resetvalue={Application Reset:0x0}
    fields as TOM[0].CH0_IRQ_MODE
  0x340 CH13_CTRL reset 0x800 — TOM0 Channel 15 Control Register resetvalue={Application Reset:0x0800}
    fields as TOM[0].CH0_CTRL
  0x344 CH13_SR0 — TOM0 Channel 15 CCU0 Compare Shadow Register resetvalue={Application Reset:0x0}
    fields as TOM[0].CH0_SR0
  0x348 CH13_SR1 — TOM0 Channel 15 CCU1 Compare Shadow Register resetvalue={Application Reset:0x0}
    fields as TOM[0].CH0_SR1
  0x34C CH13_CM0 — TOM0 Channel 15 CCU0 Compare Register resetvalue={Application Reset:0x0}
    fields as TOM[0].CH0_CM0
  0x350 CH13_CM1 — TOM0 Channel 15 CCU1 Compare Register resetvalue={Application Reset:0x0}
    fields as TOM[0].CH0_CM1
  0x354 CH13_CN0 — TOM0 Channel 15 CCU0 Counter Register resetvalue={Application Reset:0x0}
    fields as TOM[0].CH0_CN0
  0x358 CH13_STAT ro — TOM0 Channel 15 Status Register resetvalue={Application Reset:0x0}
    fields as TOM[0].CH0_STAT
  0x35C CH13_IRQ_NOTIFY — TOM0 Channel 15 Interrupt Notification Register resetvalue={Application Reset:0x0}
    fields as TOM[0].CH0_IRQ_NOTIFY
  0x360 CH13_IRQ_EN — TOM0 Channel 15 Interrupt Enable Register resetvalue={Application Reset:0x0}
    fields as TOM[0].CH0_IRQ_EN
  0x364 CH13_IRQ_FORCINT — TOM0 Channel 15 Force Interrupt Register resetvalue={Application Reset:0x0}
    fields as TOM[0].CH0_IRQ_FORCINT
  0x368 CH13_IRQ_MODE — TOM0 Channel 15 Interrupt Mode Register resetvalue={Application Reset:0x0}
    fields as TOM[0].CH0_IRQ_MODE
  0x380 CH14_CTRL reset 0x800 — TOM0 Channel 15 Control Register resetvalue={Application Reset:0x0800}
    fields as TOM[0].CH0_CTRL
  0x384 CH14_SR0 — TOM0 Channel 15 CCU0 Compare Shadow Register resetvalue={Application Reset:0x0}
    fields as TOM[0].CH0_SR0
  0x388 CH14_SR1 — TOM0 Channel 15 CCU1 Compare Shadow Register resetvalue={Application Reset:0x0}
    fields as TOM[0].CH0_SR1
  0x38C CH14_CM0 — TOM0 Channel 15 CCU0 Compare Register resetvalue={Application Reset:0x0}
    fields as TOM[0].CH0_CM0
  0x390 CH14_CM1 — TOM0 Channel 15 CCU1 Compare Register resetvalue={Application Reset:0x0}
    fields as TOM[0].CH0_CM1
  0x394 CH14_CN0 — TOM0 Channel 15 CCU0 Counter Register resetvalue={Application Reset:0x0}
    fields as TOM[0].CH0_CN0
  0x398 CH14_STAT ro — TOM0 Channel 15 Status Register resetvalue={Application Reset:0x0}
    fields as TOM[0].CH0_STAT
  0x39C CH14_IRQ_NOTIFY — TOM0 Channel 15 Interrupt Notification Register resetvalue={Application Reset:0x0}
    fields as TOM[0].CH0_IRQ_NOTIFY
  0x3A0 CH14_IRQ_EN — TOM0 Channel 15 Interrupt Enable Register resetvalue={Application Reset:0x0}
    fields as TOM[0].CH0_IRQ_EN
  0x3A4 CH14_IRQ_FORCINT — TOM0 Channel 15 Force Interrupt Register resetvalue={Application Reset:0x0}
    fields as TOM[0].CH0_IRQ_FORCINT
  0x3A8 CH14_IRQ_MODE — TOM0 Channel 15 Interrupt Mode Register resetvalue={Application Reset:0x0}
    fields as TOM[0].CH0_IRQ_MODE
  0x3C0 CH15_CTRL reset 0x800 — TOM0 Channel 15 Control Register resetvalue={Application Reset:0x0800}
    fields as TOM[0].CH0_CTRL
  0x3C4 CH15_SR0 — TOM0 Channel 15 CCU0 Compare Shadow Register resetvalue={Application Reset:0x0}
    fields as TOM[0].CH0_SR0
  0x3C8 CH15_SR1 — TOM0 Channel 15 CCU1 Compare Shadow Register resetvalue={Application Reset:0x0}
    fields as TOM[0].CH0_SR1
  0x3CC CH15_CM0 — TOM0 Channel 15 CCU0 Compare Register resetvalue={Application Reset:0x0}
    fields as TOM[0].CH0_CM0
  0x3D0 CH15_CM1 — TOM0 Channel 15 CCU1 Compare Register resetvalue={Application Reset:0x0}
    fields as TOM[0].CH0_CM1
  0x3D4 CH15_CN0 — TOM0 Channel 15 CCU0 Counter Register resetvalue={Application Reset:0x0}
    fields as TOM[0].CH0_CN0
  0x3D8 CH15_STAT ro — TOM0 Channel 15 Status Register resetvalue={Application Reset:0x0}
    fields as TOM[0].CH0_STAT
  0x3DC CH15_IRQ_NOTIFY — TOM0 Channel 15 Interrupt Notification Register resetvalue={Application Reset:0x0}
    fields as TOM[0].CH0_IRQ_NOTIFY
  0x3E0 CH15_IRQ_EN — TOM0 Channel 15 Interrupt Enable Register resetvalue={Application Reset:0x0}
    fields as TOM[0].CH0_IRQ_EN
  0x3E4 CH15_IRQ_FORCINT — TOM0 Channel 15 Force Interrupt Register resetvalue={Application Reset:0x0}
    fields as TOM[0].CH0_IRQ_FORCINT
  0x3E8 CH15_IRQ_MODE — TOM0 Channel 15 Interrupt Mode Register resetvalue={Application Reset:0x0}
    fields as TOM[0].CH0_IRQ_MODE
{0x18000+0x4000*i} PSM[{i}] (i=0..0) group
  0x00 F2A group
    {0x0+4k} RD_CH[{k}] (k=0..7) group
      0x00 F2Ai_CHz_ARU_RD_FIFO reset 0x1FE — F2A0 Stream 0 Read Address Register resetvalue={Application Reset:0x1FE}
        [8:0] ADDR — ARU Read address. This bit field is only writable if channel is disabled.
    {0x20+4k} STR_CH[{k}] (k=0..7) group
      0x00 F2Ai_CHz_STR_CFG — F2A0 Stream 0 Configuration Register resetvalue={Application Reset:0x0}
        [18] DIR — Data transfer direction
        [17:16] TMODE — Transfer mode for 53 bit ARU data from to FIFO
    0x40 F2Ai_ENABLE — F2A0 Stream Activation Register resetvalue={Application Reset:0x0}
      [2n+1:2n] STR{n}_EN (n=0..7) — Enable disable stream 7. Write of following double bit values is possible
    0x44 F2Ai_CTRL — F2A0 Stream Control Register resetvalue={Application Reset:0x0}
      [2n-7:2n-8] STR{n}_CONF (n=4..7) — Reconfiguration of stream {n} to FIFO channel {n-4}. Write of following double bit values is possible The write protected bits of register F2A i CTRL are only writable if the corresponding enable bit STR{n-4} EN and STR{n} EN of register F2A ENABLE is cleared.
  0x80 AFD group
    {0x0+0x10*k} CH[{k}] (k=0..7) group
      0x00 AFDi_CHx_BUF_ACC — AFD 0 FIFO 0 Buffer Access Register resetvalue={Application Reset:0x0}
        [28:0] DATA — Read write data from to FIFO
  0x400 FIFO group
    {0x0+0x40*k} CH[{k}] (k=0..7) group
      0x00 FIFOi_CHz_CTRL — FIFO0 Channel 0 Control Register resetvalue={Application Reset:0x0}
        [3] WULOCK — RAM write unlock. Enable disable direct RAM write access to the memory mapped FIFO region. Only the bit WULOCK of register FIFO i CH0 CTRL enables disables the direct RAM write access for all FIFO channel whole FIFO RAM . The WULOCK bits of the other channels are writeable but have no effect.
        [2] FLUSH — FIFO Flush control. A FIFO Flush operation resets the FIFO i CH z FILL LEVEL FIFO i CH z WR PTR and FIFO i CH z RD PTR registers to their initial values.
        [1] RAP — RAM access priority. RAP bit is only functional in register FIFO 0 CTRL. The priority is defined for all FIFO channels there.
        [0] RBM — Ring buffer mode enable
      0x04 FIFOi_CHz_END_ADDR reset 0x7F — FIFO0 Channel 0 End Address Register resetvalue={Application Reset:0x7F}
        [9:0] ADDR — End address for FIFO channel z. value for ADDR is calculated as ADDR 128 x 1 1 A write access will flush the regarding channel
      0x08 FIFOi_CHz_START_ADDR — FIFO0 Channel 0 Start Address Register resetvalue={Application Reset:0x0}
        [9:0] ADDR — Start address for FIFO channel z. Initial value for ADDR is calculated as ADDR 128 z. A write access will flush the regarding channel.
      0x0C FIFOi_CHz_UPPER_WM reset 0x60 — FIFO0 Channel 0 Upper Watermark Register resetvalue={Application Reset:0x60}
        [9:0] ADDR — Upper watermark address for channel z. The upper watermark is configured as a relative fill level of the FIFO. ADDR must be in range 0 lt ADDR lt FIFO i CH x END ADDR FIFO i CH x START ADDR . Initial value for ADDR is defined as ADDR 0x60.
      0x10 FIFOi_CHz_LOWER_WM reset 0x20 — FIFO0 Channel 0 Lower Watermark Register resetvalue={Application Reset:0x20}
        [9:0] ADDR — Lower watermark address for channel z. The lower watermark is configured as a relative fill level of the FIFO. ADDR must be in range 0 lt ADDR lt FIFO i CH z END ADDR FIFO i CH z START ADDR . Initial value for ADDR is defined as ADDR 0x20.
      0x14 FIFOi_CHz_STATUS ro reset 0x5 — FIFO0 Channel 0 Status Register resetvalue={Application Reset:0x5}
        [3] UP_WM — Upper watermark reached. Bit only applicable in normal mode.
        [2] LOW_WM — Lower watermark reached. Bit only applicable in normal mode.
        [1] FULL — FIFO is full. Bit only applicable in normal mode.
        [0] EMPTY — FIFO is empty. Bit only applicable in normal mode.
      0x18 FIFOi_CHz_FILL_LEVEL ro — FIFO0 Channel 0 Fill Level Register resetvalue={Application Reset:0x0}
        [10:0] LEVEL — Fill level of the current FIFO. LEVEL is in range 0 8804 LEVEL 8804 FIFO i CH z END ADDR 8722 FIFO i CH z START ADDR 1 Register content is compared to the upper and lower watermark values for this channel to detect watermark over and underflow.
      0x1C FIFOi_CHz_WR_PTR ro — FIFO0 Channel 0 Write Pointer Register resetvalue={Application Reset:0x0}
        [9:0] ADDR — Position of the write pointer. ADDR must be in range 0 lt ADDR lt 1023. Initial value for ADDR is defined as ADDR FIFO i CH z START ADDR
      0x20 FIFOi_CHz_RD_PTR ro — FIFO0 Channel 0 Read Pointer Register resetvalue={Application Reset:0x0}
        [9:0] ADDR — Position of the read pointer. ADDR must be in range 0 8804 ADDR 8804 1023. Initial value for ADDR is defined as ADDR FIFO i CH z START ADDR
      0x24 IRQ group
        0x00 FIFOi_CHz_IRQ_NOTIFY reset 0x5 — FIFO0 Channel 0 Interrupt Notification Register resetvalue={Application Reset:0x5}
          [3] FIFO_UWM — FIFO upper watermark was over run. See bit 0.
          [2] FIFO_LWM — FIFO lower watermark was under run. See bit 0.
          [1] FIFO_FULL — FIFO is full. See bit 0.
          [0] FIFO_EMPTY — FIFO is empty. This bit will be cleared on a CPU write access of value 1 . A read access leaves the bit unchanged.
        0x04 FIFOi_CHz_IRQ_EN — FIFO0 Channel 0 Interrupt Enable Register resetvalue={Application Reset:0x0}
          [3] FIFO_UWM_IRQ_EN — FIFO Upper Watermark interrupt enable
          [2] FIFO_LWM_IRQ_EN — FIFO Lower Watermark interrupt enable
          [1] FIFO_FULL_IRQ_EN — FIFO Full interrupt enable
          [0] FIFO_EMPTY_IRQ_EN — FIFO Empty interrupt enable
        0x08 FIFOi_CHz_IRQ_FORCINT — FIFO0 Channel 0 Force Interrupt Register resetvalue={Application Reset:0x0}
          [3] TRG_FIFO_UWM — Force interrupt of Upper Watermark. This bit is cleared automatically after write. This bit is write protected by bit RF PROT of register GTM CTRL.
          [2] TRG_FIFO_LWM — Force interrupt of Lower Watermark. This bit is cleared automatically after write. This bit is write protected by bit RF PROT of register GTM CTRL.
          [1] TRG_FIFO_FULL — Force interrupt of FIFO Full status. This bit is cleared automatically after write. This bit is write protected by bit RF PROT of register GTM CTRL.
          [0] TRG_FIFO_EMPTY — Force interrupt of FIFO Empty status. This bit is cleared automatically after write. This bit is write protected by bit RF PROT of register GTM CTRL
        0x0C FIFOi_CHz_IRQ_MODE — FIFO0 Channel 0 Interrupt Mode Control Register resetvalue={Application Reset:0x0}
          [3] DMA_HYST_DIR — DMA direction in hysteresis mode. In the case of DMA writing data to a FIFO the DMA requests must be generated by the lower watermark. If the DMA hysteresis is enabled the FIFO does not generate a new DMA request until the upper watermark is reached. In the case of DMA reading data from FIFO the DMA requests must be generated by the upper watermark. If the DMA hysteresis is enabled the FIFO does not generate a new DMA request until the lower watermark is reached.
          [2] DMA_HYSTERESIS — Enable DMA hysteresis mode
          [1:0] IRQ_MODE — IRQ mode selection. The interrupt modes are described in CROSSREFERENCE .
      0x34 FIFOi_CHz_EIRQ_EN — FIFO0 Channel 0 Error Interrupt Enable Register resetvalue={Application Reset:0x0}
        [3] FIFO_UWM_EIRQ_EN — FIFO Upper Watermark error interrupt enable
        [2] FIFO_LWM_EIRQ_EN — FIFO Lower Watermark error interrupt enable
        [1] FIFO_FULL_EIRQ_EN — FIFO Full error interrupt enable
        [0] FIFO_EMPTY_EIRQ_EN — FIFO Empty error interrupt enable
